VERSION "ACC_ADAS_TC016 1.0"

NS_ :

BS_:

BU_: ACC

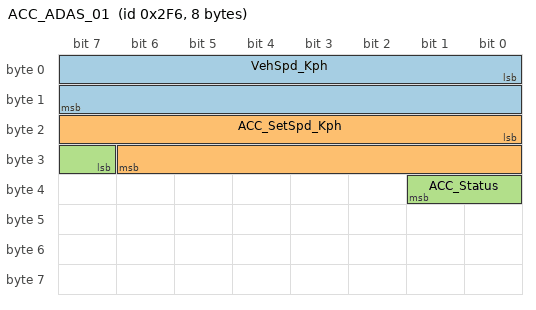
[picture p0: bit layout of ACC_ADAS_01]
BO_ 758 ACC_ADAS_01: 8 ACC
 SG_ VehSpd_Kph : 0|16@1+ (0.01,0) [0|655.35] "km/h" Vector__XXX
 SG_ ACC_SetSpd_Kph : 16|15@1+ (0.01,0) [0|327.67] "km/h" Vector__XXX
 SG_ ACC_Status : 31|3@1+ (1,0) [0|7] "1" Vector__XXX
